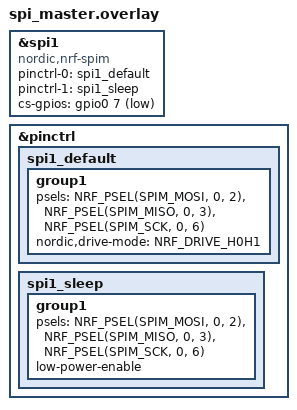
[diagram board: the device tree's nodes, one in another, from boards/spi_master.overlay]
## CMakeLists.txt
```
#
# Copyright (c) 2025 Nordic Semiconductor
#
# SPDX-License-Identifier: LicenseRef-Nordic-5-Clause
#

cmake_minimum_required(VERSION 3.20.0)

find_package(Zephyr REQUIRED HINTS $ENV{ZEPHYR_BASE})
project(nrf91_com_test)

# NORDIC SDK APP START
target_sources(app PRIVATE src/main.c)
target_sources(app PRIVATE src/spi_master_bare.c)
target_sources(app PRIVATE src/spi_slave_bare.c)
target_sources(app PRIVATE src/uart_bare.c)
target_sources(app PRIVATE src/twi_master_bare.c)
target_sources(app PRIVATE src/twi_slave_bare.c)
target_sources(app PRIVATE src/gpio.c)
# NORDIC SDK APP END

zephyr_include_directories(src)
```

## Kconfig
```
#
# Copyright (c) 2020 Nordic Semiconductor ASA
#
# SPDX-License-Identifier: LicenseRef-Nordic-5-Clause
#

menu "Zephyr Kernel"
source "Kconfig.zephyr"
endmenu

# menuconfig MY_SPI_CONFIG
#     bool "Enable SPI Test Mode"

# choice
#     prompt "SPI Mode"
#     default MY_SPI_MASTER

# config MY_SPI_MASTER
#     bool "SPI Master Mode"

# config MY_SPI_SLAVE
#     bool "SPI Slave Mode"

# endchoice
```

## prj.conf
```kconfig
#
# Copyright (c) 2024 Nordic Semiconductor ASA
#
# SPDX-License-Identifier: LicenseRef-Nordic-5-Clause
#
CONFIG_DEBUG_OPTIMIZATIONS=y
CONFIG_DEBUG_THREAD_INFO=y

CONFIG_BOOT_BANNER=n
# CONFIG_UART_CONSOLE=n

CONFIG_POSIX_API=y

CONFIG_GPIO=y
CONFIG_SPI=y
CONFIG_SPI_ASYNC=y
CONFIG_SPI_SLAVE=y
CONFIG_PM_DEVICE=y

CONFIG_I2C=y
CONFIG_I2C_TARGET=y
CONFIG_I2C_NRFX_TWIS_BUF_SIZE=8191

CONFIG_UART_ASYNC_API=y

CONFIG_TFM_LOG_LEVEL_SILENCE=y

CONFIG_DYNAMIC_INTERRUPTS=y
```

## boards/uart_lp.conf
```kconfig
CONFIG_UART_1_ASYNC=y
CONFIG_UART_1_INTERRUPT_DRIVEN=n
CONFIG_UART_1_NRF_HW_ASYNC=y
CONFIG_UART_1_NRF_HW_ASYNC_TIMER=2
CONFIG_UART_1_NRF_ASYNC_LOW_POWER=y
CONFIG_NRFX_TIMER2=y
CONFIG_NRF_SW_LPUART=y
```

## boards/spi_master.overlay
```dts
// To get started, press Ctrl+Space to bring up the completion menu and view the available nodes.

// You can also use the buttons in the sidebar to perform actions on nodes.
// Actions currently available include:

// * Enabling / disabling the node
// * Adding the bus to a bus
// * Removing the node
// * Connecting ADC channels

// For more help, browse the DeviceTree documentation at https://docs.zephyrproject.org/latest/guides/dts/index.html
// You can also visit the nRF DeviceTree extension documentation at https://docs.nordicsemi.com/bundle/nrf-connect-vscode/page/guides/ncs_configure_app.html#devicetree-support-in-the-extension

spi_master:  &spi1 {
	status = "okay";
	compatible = "nordic,nrf-spim";
	pinctrl-0 = <&spi1_default>;
	pinctrl-1 = <&spi1_sleep>;
	pinctrl-names = "default", "sleep";
	cs-gpios = <&gpio0 7 GPIO_ACTIVE_LOW>;
};

&pinctrl {
	spi1_default: spi1_default {
		group1 {
			psels = <NRF_PSEL(SPIM_MOSI, 0, 2)>,
				<NRF_PSEL(SPIM_MISO, 0, 3)>,
				<NRF_PSEL(SPIM_SCK, 0, 6)>;
				nordic,drive-mode = <NRF_DRIVE_H0H1>;
		};
	};
	spi1_sleep: spi1_sleep {
		group1 {
			psels = <NRF_PSEL(SPIM_MOSI, 0, 2)>,
				<NRF_PSEL(SPIM_MISO, 0, 3)>,
				<NRF_PSEL(SPIM_SCK, 0, 6)>;
			low-power-enable;
		};
	};
};
```

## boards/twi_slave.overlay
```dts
// To get started, press Ctrl+Space to bring up the completion menu and view the available nodes.

// You can also use the buttons in the sidebar to perform actions on nodes.
// Actions currently available include:

// * Enabling / disabling the node
// * Adding the bus to a bus
// * Removing the node
// * Connecting ADC channels

// For more help, browse the DeviceTree documentation at https://docs.zephyrproject.org/latest/guides/dts/index.html
// You can also visit the nRF DeviceTree extension documentation at https://docs.nordicsemi.com/bundle/nrf-connect-vscode/page/guides/ncs_configure_app.html#devicetree-support-in-the-extension

twi_slave:  &i2c1 {
	status = "okay";
	compatible = "nordic,nrf-twis";
	pinctrl-0 = <&i2c1_default>;
	pinctrl-1 = <&i2c1_sleep>;
	pinctrl-names = "default", "sleep";
	address-0 = <42>;
};

&pinctrl {
	i2c1_default: i2c1_default {
		group1 {
			psels = <NRF_PSEL(TWIM_SCL, 0, 2)>,
				<NRF_PSEL(TWIM_SDA, 0, 3)>;
			bias-pull-up;
		};
	};

	i2c1_sleep: i2c1_sleep {
		group1 {
			psels = <NRF_PSEL(TWIM_SCL, 0, 2)>,
				<NRF_PSEL(TWIM_SDA, 0, 3)>;
			low-power-enable;
		};
	};
};
```

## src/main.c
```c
/*
 * Copyright (c) 2024 Nordic Semiconductor ASA
 *
 * SPDX-License-Identifier: LicenseRef-Nordic-5-Clause
 *
 */

#include <stdio.h>
#include <unistd.h>
#include <zephyr/kernel.h>
#include <zephyr/logging/log.h>
#include <modem/nrf_modem_lib.h>

#define RED	"\e[0;31m"
#define GREEN	"\e[0;32m"
#define NORMAL	"\e[0m"

uint8_t tx_buffer[8*1024];
uint8_t rx_buffer[8*1024];

/* Keeping UARTE0 on drains a bit of power */
int lp_printf(const char *fmt, ...)
{
	va_list args;
	int ret;

	NRF_UARTE0_NS->ENABLE = UARTE_ENABLE_ENABLE_Enabled;

	va_start(args, fmt);
	ret = vprintf(fmt, args);
	va_end(args);

	while (!NRF_UARTE0_NS->EVENTS_ENDTX) {
		usleep(1000);
	}
	NRF_UARTE0_NS->ENABLE = 0;

	return ret;
}

void lp_print_rx(int received, int expected)
{
	lp_printf("Received %d bytes %02x%02x%02x%02x %02x%02x%02x%02x ... ", received,
			rx_buffer[0], rx_buffer[1], rx_buffer[2], rx_buffer[3],
			rx_buffer[4], rx_buffer[5], rx_buffer[6], rx_buffer[7]);

	if (received != expected) {
		lp_printf(RED "Instead of %d bytes" NORMAL, expected);
		return;

	}

	if (received != (rx_buffer[0] << 8) + rx_buffer[1]) {
		lp_printf(RED "Packet header indicates %d bytes" NORMAL,
			  (rx_buffer[0] << 8) + rx_buffer[1]);
		return;
	}

	for (int i = 2; i < received; i++) {
		if (rx_buffer[i] != (i & 0xff)) {
			lp_printf(RED "Mismatch in byte %d" NORMAL" expected %02x got %02x\n", i,
				  i & 0xff, rx_buffer[i]);
			return;
		}
	}

	lp_printf(GREEN "OK\n" NORMAL);
}

uint8_t lp_get(void)
{
	static uint8_t input;

	NRF_UARTE0_NS->ENABLE = UARTE_ENABLE_ENABLE_Enabled;

	NRF_UARTE0_NS->RXD.PTR = (int)&input;
	NRF_UARTE0_NS->RXD.MAXCNT = 1;
	NRF_UARTE0_NS->EVENTS_ENDRX = 0;
	NRF_UARTE0_NS->TASKS_STARTRX = 1;

	while (!NRF_UARTE0_NS->EVENTS_ENDRX) {
		usleep(100000);
	}

	NRF_UARTE0_NS->TASKS_STOPRX = 1;

	NRF_UARTE0_NS->ENABLE = 0;

	return input;
}

#if DT_NODE_EXISTS(DT_NODELABEL(spi_master))

/* west build -b nrf9151dk/nrf9151/ns --pristine -- -DDTC_OVERLAY_FILE=boards/spi_master.overlay */
#include "spi_master_dt.c"

#elif DT_NODE_EXISTS(DT_NODELABEL(spi_slave))

/* west build -b nrf9151dk/nrf9151/ns --pristine -- -DDTC_OVERLAY_FILE=boards/spi_slave.overlay */
#include "spi_slave_dt.c"

#elif DT_NODE_EXISTS(DT_NODELABEL(uart))

/* west build -b nrf9151dk/nrf9151/ns --pristine -- -DDTC_OVERLAY_FILE=boards/uart.overlay */
#include "uart_dt.c"

#elif DT_NODE_EXISTS(DT_NODELABEL(uart_lp))

/* west build -b nrf9151dk/nrf9151/ns --pristine -- -DDTC_OVERLAY_FILE=boards/uart_lp.overlay \
 * -DEXTRA_CONF_FILE=boards/uart_lp.conf
 */
#include "uart_lp_dt.c"

#elif DT_NODE_EXISTS(DT_NODELABEL(twi_master))

/* west build -b nrf9151dk/nrf9151/ns --pristine -- -DDTC_OVERLAY_FILE=boards/twi_master.overlay */
#include "twi_master_dt.c"

#elif DT_NODE_EXISTS(DT_NODELABEL(twi_slave))
/* Doesn't work, not supported? */
/* west build -b nrf9151dk/nrf9151/ns --pristine -- -DDTC_OVERLAY_FILE=boards/twi_slave.overlay */
#include "twi_slave_dt.c"
#else

/* Not using device tree, use runtime test selection using UART0. */

#define RAW_TEST

void spim_init(uint32_t bitrate);
int spim_send(int size);
int spim_send_delayed(int size);
int spim_recv(int size);
int spim_recv_delayed(int size);
void spim_deinit(void);

void spis_init(uint32_t bitrate);
int spis_send(int size);
int spis_recv(int size);
void spis_deinit(void);

void uart_init(uint32_t bitrate);
int uart_send(int size);
int uart_recv(int size);
void uart_deinit(void);

void uart_timeout_init(uint32_t bitrate);
void uart_timeout_deinit(void);

void uart_lp_init(uint32_t bitrate);
int uart_lp_send(int size);
int uart_lp_recv(int size);

void twim_init(uint32_t bitrate);
int twim_send(int size);
int twim_recv(int size);
void twim_deinit(void);

void twis_init(uint32_t bitrate);
int twis_send(int size);
int twis_recv(int size);
void twis_deinit(void);

void gpio_init(uint32_t bitrate);
int gpio_send(int size);
int gpio_recv(int size);
void gpio_deinit(void);

int no_send(int size)
{
	return 0;
}

int no_recv(int size)
{
	return 0;
}

void no_deinit(void)
{

}

int (*send)(int size) = no_send;
int (*recv)(int size) = no_recv;
void (*deinit)(void) = no_deinit;

typedef struct {
	char *label;
	void (*init)(uint32_t);
	uint32_t bitrate;
	int (*send)(int);
	int (*recv)(int);
	void (*deinit)(void);
} device_option_t;

char *select_device(void)
{
	char input;
	int index;
	device_option_t device_menu[] = {
		{"None (measure idle power)", NULL, 0, no_send, no_recv, no_deinit},
		{"SPI master @ 125 kbps with increased CSN to CLK delay", spim_init,
				SPIM_FREQUENCY_FREQUENCY_K125,
				spim_send_delayed, spim_recv_delayed, spim_deinit},
		{"SPI master @ 1 Mbps with increased CSN to CLK delay", spim_init,
				SPIM_FREQUENCY_FREQUENCY_M1,
				spim_send_delayed, spim_recv_delayed, spim_deinit},
		{"SPI master @ 1 Mbps", spim_init, SPIM_FREQUENCY_FREQUENCY_M1,
				spim_send, spim_recv, spim_deinit},
		{"SPI master @ 8 Mbps with increased CSN to CLK delay", spim_init,
				SPIM_FREQUENCY_FREQUENCY_M8,
				spim_send_delayed, spim_recv_delayed, spim_deinit},
		{"SPI slave", spis_init, 0, spis_send, spis_recv, spis_deinit},
		{"UART @ 115.2 kbps", uart_init, UARTE_BAUDRATE_BAUDRATE_Baud115200,
				uart_send, uart_recv, uart_deinit},
		{"UART @ 1 Mbps", uart_init, UARTE_BAUDRATE_BAUDRATE_Baud1M,
				uart_send, uart_recv, uart_deinit},
		{"UART @ 2 Mbps", uart_init, 2 * UARTE_BAUDRATE_BAUDRATE_Baud1M,
				uart_send, uart_recv, uart_deinit},
		{"UART with RX timeout @ 1 Mbps", uart_timeout_init, UARTE_BAUDRATE_BAUDRATE_Baud1M,
				uart_send, uart_recv, uart_timeout_deinit},
		{"UART with enable pins @ 1 Mbps", uart_lp_init, UARTE_BAUDRATE_BAUDRATE_Baud1M,
				uart_lp_send, uart_lp_recv, uart_deinit},
		{"TWI master @ 100 kbps", twim_init, TWIM_FREQUENCY_FREQUENCY_K100,
				twim_send, twim_recv, twim_deinit},
		{"TWI master @ 250 kbps", twim_init, TWIM_FREQUENCY_FREQUENCY_K250,
				twim_send, twim_recv, twim_deinit},
		{"TWI master @ 400 kbps", twim_init, TWIM_FREQUENCY_FREQUENCY_K400,
				twim_send, twim_recv, twim_deinit},
		{"TWI slave", twis_init, 0, twis_send, twis_recv, twis_deinit},
		{"GPIO interrupt response timing", gpio_init, 0, gpio_send, gpio_recv, gpio_deinit},
	};

	lp_printf("\nSelect peripheral:\n");
	for (index = 0; index < ARRAY_SIZE(device_menu); index++) {
		lp_printf("  %c. %s\n", 'a' + index, device_menu[index].label);
	}

	lp_printf("Configuration:\n");
	lp_printf("  [. Constant latency (keep clock on)\n");
	lp_printf("  ]. Low power mode (disable clock while idle)\n");

	input = lp_get();

	if (input == '[') {
		lp_printf("Switching to Constant latency mode\n", input);
		NRF_POWER_NS->TASKS_CONSTLAT = 1;
		return "";
	}
	if (input == ']') {
		lp_printf("Switching to low power mode\n", input);
		NRF_POWER_NS->TASKS_LOWPWR = 1;
		return "";
	}
	if (input < 'a' || input >= 'a' + ARRAY_SIZE(device_menu)) {
		lp_printf("Invalid selection '%c'\n", input);
		return "";
	}

	index = input - 'a';

	lp_printf("Selected device '%s'\n", device_menu[index].label);

	if (device_menu[index].init) {
		device_menu[index].init(device_menu[index].bitrate);
	}
	send = device_menu[index].send;
	recv = device_menu[index].recv;
	deinit = device_menu[index].deinit;

	return device_menu[index].label;
}

#endif


typedef struct {
	const char *label;
	int size;
	int (*func)(int);
} test_option_t;

int sleep_10(int size)
{
	return sleep(10);
}

int set_size_and_send(int size)
{
	tx_buffer[0] = size >> 8;
	tx_buffer[1] = size & 0xff;
	return send(size);
}

bool run_test(void)
{
	int ret;
	int input;
	test_option_t test_menu[] = {
		{"Sleep 10 s", 0, sleep_10},
		{"Send 16 bytes", 16, set_size_and_send},
		{"Send 1024 bytes", 1024, set_size_and_send},
		{"Send 8 kbytes", 8 * 1024 - 2, set_size_and_send},
		{"Receive 16 bytes", 16, recv},
		{"Receive 1024 bytes", 1024, recv},
		{"Receive 8 kbytes", 8 * 1024 - 2, recv},
	};

	lp_printf("\nSelect test:\n");
	for (int i = 0; i < ARRAY_SIZE(test_menu); i++) {
		lp_printf("  %c. %s\n", '1' + i, test_menu[i].label);
	}
	lp_printf("  Esc. Disable device\n");

	input = lp_get();

	if (input == '\e') {
		lp_printf("Disable device\n");
		return false;
	}

	input -= '1';

	if (input < 0 || input >= ARRAY_SIZE(test_menu)) {
		/* Invalid selection. */
		lp_printf("Invalid selection '%c'\n", input + '1');
		return true;
	}

	lp_printf("Selected test '%s'\n", test_menu[input].label);

	sleep(1);

	ret = test_menu[input].func(test_menu[input].size);

	sleep(1);

	if (ret == 0) {
		lp_printf("Test done\n", ret);
	} else if (ret < 0) {
		lp_printf(RED "Test returned %d\n" NORMAL, ret);
	} else {
		if (test_menu[input].label[0] == 'R') {
			lp_print_rx(ret, test_menu[input].size);
		} else if (test_menu[input].size != ret) {
			lp_printf("Send %d bytes " RED "instead of %d bytes" NORMAL "\n", ret,
				  test_menu[input].size);
		} else {
			lp_printf("Send %d bytes " GREEN "OK" NORMAL "\n", ret);
		}
	}

	return true;
}


int main(void)
{
	/* Modem is not used but always needs to be initialised to prevent 3 mA power drain. */
	nrf_modem_lib_init();

	/* Disable UART0 to reduce power. */
	NRF_UARTE0_NS->TASKS_STOPRX = 1;
	NRF_UARTE0_NS->INTEN = 0;
	NRF_UARTE0_NS->ENABLE = 0;

	lp_printf("Sample has started\n");

	for (int i = 0; i < sizeof(tx_buffer); i++) {
		tx_buffer[i] = i;
	}

	while (1) {
#ifdef RAW_TEST
		char *test_name = select_device();

		if (strlen(test_name) == 0) {
			continue;
		}
#else
		init();
#endif

		while (run_test());

		deinit();
		sleep(1);

#ifdef RAW_TEST
		lp_printf("'%s' disabled\n", test_name);
#endif
	}
}
```

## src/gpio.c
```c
/*
 * Copyright (c) 2024 Nordic Semiconductor ASA
 *
 * SPDX-License-Identifier: LicenseRef-Nordic-5-Clause
 *
 */

#include <stdio.h>
#include <unistd.h>
#include <zephyr/kernel.h>

#define GPIO        NRF_P0_NS
#define GPIOTE      NRF_GPIOTE1_NS

#define PIN_INPUT   8		/* BUTTON1 */
#define PIN_OUTPUT  0		/* LED1 */

int lp_printf(const char *fmt, ...);

static bool test_done;

 void gpio_init(uint32_t bitrate)
{
	/* Enable output pin to low. */
	GPIO->OUTCLR = 1 << PIN_OUTPUT;
	GPIO->PIN_CNF[PIN_OUTPUT] = GPIO_PIN_CNF_DIR_Output << GPIO_PIN_CNF_DIR_Pos;

	/* Enable input pin with pullup. */
	GPIO->PIN_CNF[PIN_INPUT] = GPIO_PIN_CNF_PULL_Pullup << GPIO_PIN_CNF_PULL_Pos;

	lp_printf("    Input   P0.%02d\n", PIN_INPUT);
	lp_printf("    Output  P0.%02d\n", PIN_OUTPUT);
	lp_printf("Select 'Receive' and pull input low to measure response time on output\n");
}

int gpio_send(int size)
{
	/* Output pin high. */
	GPIO->OUTSET = 1 << PIN_OUTPUT;

	sleep(1);

	/* Output pin low. */
	GPIO->OUTCLR = 1 << PIN_OUTPUT;

	return 0;
}

void gpiote_isr(const void *arg)
{
	/* Output pin low. */
	GPIO->OUTCLR = 1 << PIN_OUTPUT;

	/* Clear interrupt. */
	GPIOTE->INTENCLR = GPIOTE_INTENCLR_IN0_Msk;

	test_done = true;
}

int gpio_recv(int size)
{
	test_done = false;

	/* Output pin high. */
	GPIO->OUTSET = 1 << PIN_OUTPUT;

	/* Enable interrupt. */
	GPIOTE->CONFIG[0] = GPIOTE_CONFIG_MODE_Event << GPIOTE_CONFIG_MODE_Pos |
			    PIN_INPUT << GPIOTE_CONFIG_PSEL_Pos |
			    GPIOTE_CONFIG_POLARITY_HiToLo << GPIOTE_CONFIG_POLARITY_Pos;
	GPIOTE->EVENTS_IN[0] = 0;
	GPIOTE->INTENSET = GPIOTE_INTENSET_IN0_Msk;
	irq_connect_dynamic(GPIOTE1_IRQn, 0, gpiote_isr, NULL, 0);
	irq_enable(GPIOTE1_IRQn);

	while (!test_done) {
		__WFI();
	}

	/* Disable interrupt. */
	irq_disable(GPIOTE1_IRQn);
	GPIOTE->INTENCLR = GPIOTE_INTENCLR_IN0_Msk;

	/* Output pin low. */
	GPIO->OUTCLR = 1 << PIN_OUTPUT;

	return 0;//87.8 µs 11.5 µs 76.3
}

void gpio_deinit(void)
{
	/* Disable output pin. */
	GPIO->OUTCLR = 1 << PIN_OUTPUT;
	GPIO->PIN_CNF[PIN_OUTPUT] = 0;

	/* Disable input pin. */
	GPIO->PIN_CNF[PIN_INPUT] = 0;
}
```

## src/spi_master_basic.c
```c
/*
 * Copyright (c) 2024 Nordic Semiconductor ASA
 *
 * SPDX-License-Identifier: LicenseRef-Nordic-5-Clause
 *
 */

#include <stdio.h>
#include <unistd.h>
#include <zephyr/kernel.h>

#define SPI_MASTER NRF_SPIM1_NS
#define GPIO       NRF_P0_NS
#define PIN_SCK    6
#define PIN_MISO   3
#define PIN_MOSI   2
#define PIN_CS     7

extern uint8_t tx_buffer[1024];
extern uint8_t rx_buffer[2048];

int lp_printf(const char *fmt, ...);

K_SEM_DEFINE(spim_done, 0, 1);

void spim_isr(const void *arg)
{
	SPI_MASTER->EVENTS_END = 0;
	k_sem_give(&spim_done);
}

void spim_init(uint32_t bitrate)
{
	/* MISO: Dir input, input connect, pull disabled, drive s0s1, sense disabled. */
	GPIO->PIN_CNF[PIN_MISO] = 0;

	/* Configure pins. */
	SPI_MASTER->PSEL.SCK = PIN_SCK;
	SPI_MASTER->PSEL.MOSI = PIN_MOSI;
	SPI_MASTER->PSEL.MISO = PIN_MISO;

	/* Configure buffers. */
	SPI_MASTER->RXD.PTR = (int)rx_buffer;
	SPI_MASTER->TXD.PTR = (int)tx_buffer;

	/* Most significant bit first, Sample on trailing edge, Active low.  */
	SPI_MASTER->CONFIG = SPIS_CONFIG_CPOL_Msk | SPIS_CONFIG_CPHA_Msk;

	/* Frequency */
	SPI_MASTER->FREQUENCY = bitrate;

	/* Enable interrupt to wake up at the end of a message. */
	SPI_MASTER->INTENSET = SPIM_INTENSET_END_Msk;
	irq_connect_dynamic(SPIM1_SPIS1_TWIM1_TWIS1_UARTE1_IRQn, 0, spim_isr, NULL, 0);
	irq_enable(SPIM1_SPIS1_TWIM1_TWIS1_UARTE1_IRQn);

	/* Enable. */
	SPI_MASTER->ENABLE = SPIM_ENABLE_ENABLE_Enabled;

	/* SCK: Dir output, input disconnect, pull disabled, drive h0h1, sense disabled. */
	GPIO->PIN_CNF[PIN_SCK] = (GPIO_PIN_CNF_DIR_Output << GPIO_PIN_CNF_DIR_Pos) |
				 (GPIO_PIN_CNF_INPUT_Disconnect << GPIO_PIN_CNF_INPUT_Pos) |
				 (GPIO_PIN_CNF_DRIVE_H0H1 << GPIO_PIN_CNF_DRIVE_Pos);
	/* MOSI: Dir output, input disconnect, pull disabled, drive h0h1, sense disabled. */
	GPIO->PIN_CNF[PIN_MOSI] = (GPIO_PIN_CNF_DIR_Output << GPIO_PIN_CNF_DIR_Pos) |
				  (GPIO_PIN_CNF_INPUT_Disconnect << GPIO_PIN_CNF_INPUT_Pos) |
				  (GPIO_PIN_CNF_DRIVE_H0H1 << GPIO_PIN_CNF_DRIVE_Pos);
	/* CS: high. */
	GPIO->OUTSET = 1 << PIN_CS;
	/* CS: Dir output, input disconnect, pull disabled, drive h0h1, sense disabled. */
	GPIO->PIN_CNF[PIN_CS] = (GPIO_PIN_CNF_DIR_Output << GPIO_PIN_CNF_DIR_Pos) |
				(GPIO_PIN_CNF_INPUT_Disconnect << GPIO_PIN_CNF_INPUT_Pos) |
				(GPIO_PIN_CNF_DRIVE_H0H1 << GPIO_PIN_CNF_DRIVE_Pos);

	lp_printf("    SCK     P0.%02d\n", PIN_SCK);
	lp_printf("    MOSI    P0.%02d\n", PIN_MOSI);
	lp_printf("    MISO    P0.%02d\n", PIN_MISO);
	lp_printf("    CS      P0.%02d\n", PIN_CS);
}

int spim_send(int size)
{
	SPI_MASTER->TXD.MAXCNT = size;
	SPI_MASTER->RXD.MAXCNT = 0;

	/* CS: low. */
	GPIO->OUTCLR = 1 << PIN_CS;

	SPI_MASTER->TASKS_START = 1;

	k_sem_take(&spim_done, K_FOREVER);

	/* CS: high. */
	GPIO->OUTSET = 1 << PIN_CS;

	return SPI_MASTER->TXD.AMOUNT;
}

int spim_send_delayed(int size)
{
	SPI_MASTER->TXD.MAXCNT = size;
	SPI_MASTER->RXD.MAXCNT = 0;

	/* CS: low. */
	GPIO->OUTCLR = 1 << PIN_CS;

	usleep(80);

	SPI_MASTER->TASKS_START = 1;

	k_sem_take(&spim_done, K_FOREVER);

	usleep(1);

	/* CS: high. */
	GPIO->OUTSET = 1 << PIN_CS;

	return SPI_MASTER->TXD.AMOUNT;
}

int spim_recv(int size)
{
	SPI_MASTER->TXD.MAXCNT = 0;
	SPI_MASTER->RXD.MAXCNT = size;

	/* CS: low. */
	GPIO->OUTCLR = 1 << PIN_CS;

	SPI_MASTER->TASKS_START = 1;

	k_sem_take(&spim_done, K_FOREVER);

	/* CS: high. */
	GPIO->OUTSET = 1 << PIN_CS;

	return SPI_MASTER->RXD.AMOUNT;
}

int spim_recv_delayed(int size)
{
	SPI_MASTER->TXD.MAXCNT = 0;
	SPI_MASTER->RXD.MAXCNT = size;

	/* CS: low. */
	GPIO->OUTCLR = 1 << PIN_CS;

	usleep(80);

	SPI_MASTER->TASKS_START = 1;

	k_sem_take(&spim_done, K_FOREVER);

	usleep(1);

	/* CS: high. */
	GPIO->OUTSET = 1 << PIN_CS;

	return SPI_MASTER->RXD.AMOUNT;
}

void spim_deinit(void)
{
	SPI_MASTER->INTENCLR = SPIM_INTENCLR_END_Msk;
	GPIO->PIN_CNF[PIN_SCK] = 0;
	GPIO->PIN_CNF[2] = 0;
	GPIO->PIN_CNF[PIN_CS] = 0;
	SPI_MASTER->ENABLE = 0;
}
```

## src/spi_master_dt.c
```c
/*
 * Copyright (c) 2024 Nordic Semiconductor ASA
 *
 * SPDX-License-Identifier: LicenseRef-Nordic-5-Clause
 *
 */

#include <zephyr/drivers/spi.h>
#include <zephyr/pm/device.h>

#define USED_DEV DT_NODELABEL(spi_master)
#define DT_DRV_COMPAT nordic_nrf_spim
#define SPI_MASTER NRF_SPIM1_NS

const struct device *p_dev;
struct spi_config spi_cfg = {
	.operation = SPI_WORD_SET(8) | SPI_TRANSFER_MSB | SPI_MODE_CPOL | SPI_MODE_CPHA,
	.frequency = 1000000,
	.slave = 0,
	.cs.gpio = GPIO_DT_SPEC_INST_GET(0, cs_gpios),
	.cs.delay = 100,
};

void init(void)
{
	p_dev = DEVICE_DT_GET(USED_DEV);

	if (p_dev == NULL) {
		lp_printf("Could not get device\n");
		return;
	}
	lp_printf("\nUsing SPI Master device: %s\n", p_dev->name);
	lp_printf("    SCK     P0.%02d\n", SPI_MASTER->PSEL.SCK);
	lp_printf("    MOSI    P0.%02d\n", SPI_MASTER->PSEL.MOSI);
	lp_printf("    MISO    P0.%02d\n", SPI_MASTER->PSEL.MISO);
	lp_printf("    CS      P0.%02d\n", spi_cfg.cs.gpio.pin);

	pm_device_action_run(p_dev, PM_DEVICE_ACTION_RESUME);
}

int send(int size)
{
	int err;

	const struct spi_buf tx_buf = {
		.buf = tx_buffer,
		.len = size
	};
	const struct spi_buf_set tx = {
		.buffers = &tx_buf,
		.count = 1
	};

	err = spi_write(p_dev, &spi_cfg, &tx);

	return err == 0 ? size : err;
}

int recv(int size)
{
	int err;

	struct spi_buf rx_buf = {
		.buf = rx_buffer,
		.len = size,
	};
	const struct spi_buf_set rx = {
		.buffers = &rx_buf,
		.count = 1
	};

	err = spi_read(p_dev, &spi_cfg, &rx);

	return err == 0 ? size : err;
}

void deinit(void)
{
	spi_release(p_dev, &spi_cfg);
	/* Suspend is needed to re-initialise SPIM so we can change the frequency. */
	pm_device_action_run(p_dev, PM_DEVICE_ACTION_SUSPEND);
}
```

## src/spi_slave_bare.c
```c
/*
 * Copyright (c) 2024 Nordic Semiconductor ASA
 *
 * SPDX-License-Identifier: LicenseRef-Nordic-5-Clause
 *
 */

#include <stdio.h>
#include <unistd.h>
#include <zephyr/kernel.h>

#define SPI_SLAVE NRF_SPIS1_NS
#define GPIO      NRF_P0_NS
#define PIN_SCK    6
#define PIN_MISO   3
#define PIN_MOSI   2
#define PIN_CS     7

extern uint8_t tx_buffer[1024];
extern uint8_t rx_buffer[2048];

K_SEM_DEFINE(spis_done, 0, 1);

int lp_printf(const char *fmt, ...);

static void spis_isr(const void *arg)
{
	SPI_SLAVE->EVENTS_END = 0;
	k_sem_give(&spis_done);
}

void spis_init(uint32_t bitrate)
{
	/* SCK: Dir input, input connect, pull disabled, drive s0s1, sense disabled. */
	GPIO->PIN_CNF[PIN_SCK] = 0;
	/* MOSI: Dir input, input connect, pull disabled, drive s0s1, sense disabled. */
	GPIO->PIN_CNF[PIN_MOSI] = 0;
	/* CSN: Dir input, input connect, pull disabled, drive s0s1, sense disabled. */
	GPIO->PIN_CNF[PIN_CS] = 0;

	/* Configure pins. */
	SPI_SLAVE->PSEL.SCK = PIN_SCK;
	SPI_SLAVE->PSEL.MISO = PIN_MISO;
	SPI_SLAVE->PSEL.MOSI = PIN_MOSI;
	SPI_SLAVE->PSEL.CSN = PIN_CS;

	/* Configure buffers. */
	SPI_SLAVE->RXD.PTR = (int)rx_buffer;
	SPI_SLAVE->TXD.PTR = (int)tx_buffer;

	/* Most significant bit first, Sample on trailing edge, Active low.  */
	SPI_SLAVE->CONFIG = SPIS_CONFIG_CPOL_Msk | SPIS_CONFIG_CPHA_Msk;

	/* Equire semaphore on end of transmission. */
	SPI_SLAVE->SHORTS = SPIS_SHORTS_END_ACQUIRE_Msk;

	/* Enable interrupt to wake up at the end of a message. */
	SPI_SLAVE->INTENSET = SPIS_INTENSET_END_Msk;
	irq_connect_dynamic(SPIM1_SPIS1_TWIM1_TWIS1_UARTE1_IRQn, 0, spis_isr, NULL, 0);
	irq_enable(SPIM1_SPIS1_TWIM1_TWIS1_UARTE1_IRQn);

	/* Enable. */
	SPI_SLAVE->ENABLE = SPIS_ENABLE_ENABLE_Enabled;

	/* MISO: Dir output, input disconnect, pull disabled, drive h0h1, sense disabled. */
	GPIO->PIN_CNF[PIN_MISO] = (GPIO_PIN_CNF_DIR_Output << GPIO_PIN_CNF_DIR_Pos) |
				  (GPIO_PIN_CNF_INPUT_Disconnect << GPIO_PIN_CNF_INPUT_Pos) |
				  (GPIO_PIN_CNF_DRIVE_H0H1 << GPIO_PIN_CNF_DRIVE_Pos);

	lp_printf("    SCK     P0.%02d\n", PIN_SCK);
	lp_printf("    MOSI    P0.%02d\n", PIN_MOSI);
	lp_printf("    MISO    P0.%02d\n", PIN_MISO);
	lp_printf("    CS      P0.%02d\n", PIN_CS);
}

int spis_send(int size)
{
	SPI_SLAVE->TXD.MAXCNT = size;
	SPI_SLAVE->RXD.MAXCNT = 0;
	SPI_SLAVE->TASKS_RELEASE = 1;

	if (k_sem_take(&spis_done,  K_SECONDS(60))) {
		SPI_SLAVE->TASKS_ACQUIRE = 1;
		return -ETIMEDOUT;
	}

	return SPI_SLAVE->TXD.AMOUNT;
}

int spis_recv(int size)
{
	SPI_SLAVE->TXD.MAXCNT = 0;
	SPI_SLAVE->RXD.MAXCNT = size;
	SPI_SLAVE->TASKS_RELEASE = 1;

	if (k_sem_take(&spis_done,  K_SECONDS(60))) {
		SPI_SLAVE->TASKS_ACQUIRE = 1;
		return -ETIMEDOUT;
	}

	return SPI_SLAVE->RXD.AMOUNT;
}

void spis_deinit(void)
{
	SPI_SLAVE->INTENCLR = SPIS_INTENCLR_END_Msk;
	GPIO->PIN_CNF[PIN_MISO] = 0;
	SPI_SLAVE->ENABLE = 0;
}
```

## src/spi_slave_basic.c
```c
/*
 * Copyright (c) 2024 Nordic Semiconductor ASA
 *
 * SPDX-License-Identifier: LicenseRef-Nordic-5-Clause
 *
 */

#include <stdio.h>
#include <unistd.h>
#include <zephyr/kernel.h>

#define SPI_SLAVE NRF_SPIS1_NS
#define GPIO      NRF_P0_NS
#define PIN_SCK    6
#define PIN_MISO   3
#define PIN_MOSI   2
#define PIN_CS     7

extern uint8_t tx_buffer[1024];
extern uint8_t rx_buffer[2048];

int lp_printf(const char *fmt, ...);

static bool transfer_done = false;

static void spis_isr(const void *arg)
{
	transfer_done = true;
	SPI_SLAVE->EVENTS_END = 0;
}

void spis_init(uint32_t bitrate)
{
	/* SCK: Dir input, input connect, pull disabled, drive s0s1, sense disabled. */
	GPIO->PIN_CNF[PIN_SCK] = 0;
	/* MOSI: Dir input, input connect, pull disabled, drive s0s1, sense disabled. */
	GPIO->PIN_CNF[PIN_MOSI] = 0;
	/* CSN: Dir input, input connect, pull disabled, drive s0s1, sense disabled. */
	GPIO->PIN_CNF[PIN_CS] = 0;

	/* Configure pins. */
	SPI_SLAVE->PSEL.SCK = PIN_SCK;
	SPI_SLAVE->PSEL.MISO = PIN_MISO;
	SPI_SLAVE->PSEL.MOSI = PIN_MOSI;
	SPI_SLAVE->PSEL.CSN = PIN_CS;

	/* Configure buffers. */
	SPI_SLAVE->RXD.PTR = (int)rx_buffer;
	SPI_SLAVE->TXD.PTR = (int)tx_buffer;

	/* Most significant bit first, Sample on trailing edge, Active low.  */
	SPI_SLAVE->CONFIG = SPIS_CONFIG_CPOL_Msk | SPIS_CONFIG_CPHA_Msk;

	/* Equire semaphore on end of transmission. */
	SPI_SLAVE->SHORTS = SPIS_SHORTS_END_ACQUIRE_Msk;

	/* Enable interrupt to wake up at the end of a message. */
	SPI_SLAVE->INTENSET = SPIS_INTENSET_END_Msk;
	irq_connect_dynamic(SPIM1_SPIS1_TWIM1_TWIS1_UARTE1_IRQn, 0, spis_isr, NULL, 0);
	irq_enable(SPIM1_SPIS1_TWIM1_TWIS1_UARTE1_IRQn);

	/* Enable. */
	SPI_SLAVE->ENABLE = SPIS_ENABLE_ENABLE_Enabled;

	/* MISO: Dir output, input disconnect, pull disabled, drive h0h1, sense disabled. */
	GPIO->PIN_CNF[PIN_MISO] = (GPIO_PIN_CNF_DIR_Output << GPIO_PIN_CNF_DIR_Pos) |
				  (GPIO_PIN_CNF_INPUT_Disconnect << GPIO_PIN_CNF_INPUT_Pos) |
				  (GPIO_PIN_CNF_DRIVE_H0H1 << GPIO_PIN_CNF_DRIVE_Pos);

	lp_printf("    SCK     P0.%02d\n", PIN_SCK);
	lp_printf("    MOSI    P0.%02d\n", PIN_MOSI);
	lp_printf("    MISO    P0.%02d\n", PIN_MISO);
	lp_printf("    CS      P0.%02d\n", PIN_CS);
}

int spis_send(int size)
{
	SPI_SLAVE->TXD.MAXCNT = size;
	SPI_SLAVE->RXD.MAXCNT = 0;
	SPI_SLAVE->TASKS_RELEASE = 1;

	while (!transfer_done) {
		__WFI();
	}

	transfer_done = false;

	return SPI_SLAVE->TXD.AMOUNT;
}

int spis_recv(int size)
{
	SPI_SLAVE->TXD.MAXCNT = 0;
	SPI_SLAVE->RXD.MAXCNT = size;
	SPI_SLAVE->TASKS_RELEASE = 1;

	while (!transfer_done) {
		__WFI();
	}

	transfer_done = false;

	return SPI_SLAVE->RXD.AMOUNT;
}

void spis_deinit(void)
{
	SPI_SLAVE->INTENCLR = SPIS_INTENCLR_END_Msk;
	GPIO->PIN_CNF[PIN_MISO] = 0;
	SPI_SLAVE->ENABLE = 0;
}
```

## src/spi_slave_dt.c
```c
/*
 * Copyright (c) 2024 Nordic Semiconductor ASA
 *
 * SPDX-License-Identifier: LicenseRef-Nordic-5-Clause
 *
 */

#include <zephyr/drivers/spi.h>
#include <../../modules/hal/nordic/nrfx/hal/nrf_spis.h>

#define USED_DEV DT_NODELABEL(spi_slave)
#define SPI_SLAVE NRF_SPIS1_NS

const struct device *p_dev;

void init(void)
{
	p_dev = DEVICE_DT_GET(USED_DEV);

	if (p_dev == NULL) {
		lp_printf("Could not get device\n");
		return;
	}
	lp_printf("\nUsing SPI Slave device: %s\n", p_dev->name);
	lp_printf("    SCK     P0.%02d\n", SPI_SLAVE->PSEL.SCK);
	lp_printf("    MOSI    P0.%02d\n", SPI_SLAVE->PSEL.MOSI);
	lp_printf("    MISO    P0.%02d\n", SPI_SLAVE->PSEL.MISO);
	lp_printf("    CS      P0.%02d\n", SPI_SLAVE->PSEL.CSN);
}

static const struct spi_config spi_cfg = {
	.operation = SPI_WORD_SET(8) | SPI_TRANSFER_MSB | SPI_OP_MODE_SLAVE |
		     SPI_MODE_CPOL | SPI_MODE_CPHA,
	.frequency = 1000000,
	.slave = 1,
};

int send(int size)
{
	const struct spi_buf tx_buf = {
		.buf = tx_buffer,
		.len = size
	};
	const struct spi_buf_set tx = {
		.buffers = &tx_buf,
		.count = 1
	};

	/* Always returns 0, how do we tell how many bytes were send? */
	return spi_write(p_dev, &spi_cfg, &tx);
}

int recv(int size)
{
	struct spi_buf rx_buf = {
		.buf = rx_buffer,
		.len = size
	};
	const struct spi_buf_set rx = {
		.buffers = &rx_buf,
		.count = 1
	};

	return spi_read(p_dev, &spi_cfg, &rx);
}

void deinit(void)
{

}
```

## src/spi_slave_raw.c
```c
/*
 * Copyright (c) 2024 Nordic Semiconductor ASA
 *
 * SPDX-License-Identifier: LicenseRef-Nordic-5-Clause
 *
 */

#include <stdio.h>
#include <unistd.h>
#include <zephyr/kernel.h>
#include <zephyr/logging/log.h>
LOG_MODULE_REGISTER(spi, LOG_LEVEL_DBG);

#define SPI_SLAVE NRF_SPIS1_NS
#define GPIO      NRF_P0_NS

extern uint8_t tx_buffer[1024];
extern uint8_t rx_buffer[2048];

void spi_slave_init(void)
{
	GPIO->PIN_CNF[2] = 0x300;
	GPIO->PIN_CNF[3] = 0x302;
	GPIO->PIN_CNF[6] = 0x300;
	GPIO->PIN_CNF[7] = 0x300;

	SPI_SLAVE->PSEL.SCK = 6;
	SPI_SLAVE->PSEL.MISO = 3;
	SPI_SLAVE->PSEL.MOSI = 2;
	SPI_SLAVE->PSEL.CSN = 7;
	SPI_SLAVE->RXD.PTR = (int)rx_buffer;
	SPI_SLAVE->RXD.MAXCNT = sizeof(rx_buffer);
	SPI_SLAVE->TXD.PTR = (int)tx_buffer;
	SPI_SLAVE->TXD.MAXCNT = sizeof(tx_buffer);
	SPI_SLAVE->CONFIG = SPIS_CONFIG_CPOL_Msk | SPIS_CONFIG_CPHA_Msk;
	SPI_SLAVE->SHORTS = 4;
	SPI_SLAVE->ENABLE = 2;

	SPI_SLAVE->TASKS_RELEASE = 1;
}

void spi_slave_test(size_t size)
{
	while (1) {
		while (!SPI_SLAVE->EVENTS_END) {
			sleep(1);
		}

		printf("\nReceived %d\n", SPI_SLAVE->RXD.AMOUNT);
		printf("success %d: %02x %02x %02x %02x\n", (rx_buffer[0] << 8) + rx_buffer[1],
		       rx_buffer[2], rx_buffer[3], rx_buffer[4], rx_buffer[5]);
		printf("status %x\n", SPI_SLAVE->STATUS);
		printf("send %d\n", SPI_SLAVE->TXD.AMOUNT);
		SPI_SLAVE->EVENTS_END = 0;
		SPI_SLAVE->TASKS_RELEASE = 1;
	}
}

void spi_slave_deinit(void)
{

}
```

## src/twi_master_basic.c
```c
/*
 * Copyright (c) 2024 Nordic Semiconductor ASA
 *
 * SPDX-License-Identifier: LicenseRef-Nordic-5-Clause
 *
 */

#include <stdio.h>
#include <unistd.h>
#include <zephyr/kernel.h>

#define TWI_MASTER NRF_TWIM1_NS
#define GPIO       NRF_P0_NS
#define PIN_SCL    2
#define PIN_SDA    3

extern uint8_t tx_buffer[1024];
extern uint8_t rx_buffer[2048];

int lp_printf(const char *fmt, ...);

K_SEM_DEFINE(twim_done, 0, 1);
static bool error = false;

void twim_isr(const void *arg)
{
	if (TWI_MASTER->EVENTS_STOPPED) {
		TWI_MASTER->EVENTS_STOPPED = 0;
	}
	if (TWI_MASTER->EVENTS_ERROR) {
		error = true;
		TWI_MASTER->EVENTS_ERROR = 0;
	}
	k_sem_give(&twim_done);
}

void twim_init(uint32_t bitrate)
{
	/* SCK: Dir input, input disconnect, pull up, drive s0d1, sense disabled. */
	GPIO->PIN_CNF[PIN_SCL] = (GPIO_PIN_CNF_INPUT_Disconnect << GPIO_PIN_CNF_INPUT_Pos) |
				 (GPIO_PIN_CNF_PULL_Pullup << GPIO_PIN_CNF_PULL_Pos) |
				 (GPIO_PIN_CNF_DRIVE_S0D1 << GPIO_PIN_CNF_DRIVE_Pos);
	/* MOSI: Dir input, input disconnect, pull up, drive s0d1, sense disabled. */
	GPIO->PIN_CNF[PIN_SDA] = (GPIO_PIN_CNF_INPUT_Disconnect << GPIO_PIN_CNF_INPUT_Pos) |
				 (GPIO_PIN_CNF_PULL_Pullup << GPIO_PIN_CNF_PULL_Pos) |
				 (GPIO_PIN_CNF_DRIVE_S0D1 << GPIO_PIN_CNF_DRIVE_Pos);

	/* Configure pins. */
	TWI_MASTER->PSEL.SCL = PIN_SCL;
	TWI_MASTER->PSEL.SDA = PIN_SDA;

	/* Configure buffers. */
	TWI_MASTER->RXD.PTR = (int)rx_buffer;
	TWI_MASTER->TXD.PTR = (int)tx_buffer;

	/* Configure. */
	TWI_MASTER->FREQUENCY = bitrate;
	TWI_MASTER->ADDRESS = 42;

	/* Stop after transfer. */
	TWI_MASTER->SHORTS = TWIM_SHORTS_LASTTX_STOP_Msk | TWIM_SHORTS_LASTRX_STOP_Msk;

	/* Enable interrupt to wake up at the end of a message. */
	TWI_MASTER->INTENSET = TWIM_INTENSET_STOPPED_Msk | TWIM_INTENSET_ERROR_Msk;
	irq_connect_dynamic(SPIM1_SPIS1_TWIM1_TWIS1_UARTE1_IRQn, 0, twim_isr, NULL, 0);
	irq_enable(SPIM1_SPIS1_TWIM1_TWIS1_UARTE1_IRQn);

	/* Enable. */
	TWI_MASTER->ENABLE = TWIM_ENABLE_ENABLE_Enabled;

	lp_printf("    SCL     P0.%02d\n", PIN_SCL);
	lp_printf("    SDA     P0.%02d\n", PIN_SDA);
}

int twim_send(int size)
{
	int err = 0;

	error = false;

	TWI_MASTER->TXD.MAXCNT = size;
	TWI_MASTER->TASKS_STARTTX = 1;

	k_sem_take(&twim_done, K_FOREVER);

	if (error) {
		err = TWI_MASTER->ERRORSRC;
		TWI_MASTER->ERRORSRC = err;
		TWI_MASTER->TASKS_STOP = 1;
		k_sem_take(&twim_done, K_FOREVER);
		return -err;
	}

	return TWI_MASTER->TXD.AMOUNT;
}

int twim_recv(int size)
{
	int err = 0;

	error = false;

	TWI_MASTER->RXD.MAXCNT = size;
	TWI_MASTER->TASKS_STARTRX = 1;

	k_sem_take(&twim_done, K_FOREVER);

	if (error) {
		err = TWI_MASTER->ERRORSRC;
		TWI_MASTER->ERRORSRC = err;
		TWI_MASTER->TASKS_STOP = 1;
		k_sem_take(&twim_done, K_FOREVER);
		return -err;
	}

	return TWI_MASTER->RXD.AMOUNT;
}

void twim_deinit(void)
{
	TWI_MASTER->INTENCLR = TWIM_INTENCLR_STOPPED_Msk| TWIM_INTENCLR_ERROR_Msk;
	TWI_MASTER->SHORTS = 0;
	GPIO->PIN_CNF[PIN_SCL] = 0;
	GPIO->PIN_CNF[PIN_SDA] = 0;
	TWI_MASTER->ENABLE = 0;
}
```

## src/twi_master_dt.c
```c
/*
 * Copyright (c) 2024 Nordic Semiconductor ASA
 *
 * SPDX-License-Identifier: LicenseRef-Nordic-5-Clause
 *
 */

#include <zephyr/drivers/i2c.h>
#include <zephyr/pm/device.h>

#define USED_DEV DT_NODELABEL(twi_master)
#define DT_DRV_COMPAT nordic_nrf_twim

const struct device *p_dev;

void init(void)
{
	p_dev = DEVICE_DT_GET(USED_DEV);

	if (p_dev == NULL) {
		lp_printf("Could not get device\n");
		return;
	}
	lp_printf("\nUsing TWI Master device %s\n", p_dev->name);
}

void send(int size)
{
	int err = i2c_write(p_dev, tx_buffer, size, 42);

	lp_printf("err = %d\n", err);
}

int recv(int size, int timeout)
{
	return i2c_read(p_dev, rx_buffer, size, 42);
}

void deinit(void)
{

}
```

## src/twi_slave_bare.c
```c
/*
 * Copyright (c) 2024 Nordic Semiconductor ASA
 *
 * SPDX-License-Identifier: LicenseRef-Nordic-5-Clause
 *
 */

#include <stdio.h>
#include <unistd.h>
#include <zephyr/kernel.h>

#define TWI_SLAVE  NRF_TWIS1_NS
#define GPIO       NRF_P0_NS
#define PIN_SCL    2
#define PIN_SDA    3

extern uint8_t tx_buffer[1024];
extern uint8_t rx_buffer[2048];

int lp_printf(const char *fmt, ...);

K_SEM_DEFINE(twis_done, 0, 1);

void twis_isr(const void *arg)
{
	if (TWI_SLAVE->EVENTS_STOPPED) {
		k_sem_give(&twis_done);
		TWI_SLAVE->EVENTS_STOPPED = 0;
	}
	if (TWI_SLAVE->EVENTS_READ) {
		TWI_SLAVE->TASKS_PREPARETX = 1;
		TWI_SLAVE->TASKS_RESUME = 1;
		TWI_SLAVE->EVENTS_READ = 0;
	}
	if (TWI_SLAVE->EVENTS_WRITE) {
		TWI_SLAVE->TASKS_PREPARERX = 1;
		TWI_SLAVE->TASKS_RESUME = 1;
		TWI_SLAVE->EVENTS_WRITE = 0;
	}
}

void twis_init(uint32_t bitrate)
{
	/* SCK: Dir output, input disconnect, pull up, drive h0d1, sense disabled. */
	GPIO->PIN_CNF[PIN_SCL] = (GPIO_PIN_CNF_INPUT_Disconnect << GPIO_PIN_CNF_INPUT_Pos) |
				 (GPIO_PIN_CNF_PULL_Pullup << GPIO_PIN_CNF_PULL_Pos) |
				 (GPIO_PIN_CNF_DRIVE_S0D1 << GPIO_PIN_CNF_DRIVE_Pos);
	/* MOSI: Dir output, input disconnect, pull up, drive h0d1, sense disabled. */
	GPIO->PIN_CNF[PIN_SDA] = (GPIO_PIN_CNF_INPUT_Disconnect << GPIO_PIN_CNF_INPUT_Pos) |
				 (GPIO_PIN_CNF_PULL_Pullup << GPIO_PIN_CNF_PULL_Pos) |
				 (GPIO_PIN_CNF_DRIVE_S0D1 << GPIO_PIN_CNF_DRIVE_Pos);

	/* Configure pins. */
	TWI_SLAVE->PSEL.SCL = PIN_SCL;
	TWI_SLAVE->PSEL.SDA = PIN_SDA;

	/* Configure buffers. */
	TWI_SLAVE->RXD.PTR = (int)rx_buffer;
	TWI_SLAVE->RXD.MAXCNT = 0;
	TWI_SLAVE->TXD.PTR = (int)tx_buffer;
	TWI_SLAVE->TXD.MAXCNT = 0;

	/* Configure. */
	TWI_SLAVE->ADDRESS[0] = 42;
	TWI_SLAVE->CONFIG = TWIS_CONFIG_ADDRESS0_Msk;
	/* Suspend after we have received a READ or WRITE flag so we can either start RX or TX. */
	TWI_SLAVE->SHORTS = TWIS_SHORTS_READ_SUSPEND_Msk | TWIS_SHORTS_WRITE_SUSPEND_Msk;

	/* Enable interrupt to wake up at the end of a message. */
	TWI_SLAVE->INTENSET = TWIS_INTENSET_STOPPED_Msk | TWIS_INTENSET_READ_Msk |
			      TWIS_INTENSET_WRITE_Msk;
	irq_connect_dynamic(SPIM1_SPIS1_TWIM1_TWIS1_UARTE1_IRQn, 0, twis_isr, NULL, 0);
	irq_enable(SPIM1_SPIS1_TWIM1_TWIS1_UARTE1_IRQn);

	/* Enable. */
	TWI_SLAVE->ENABLE = TWIS_ENABLE_ENABLE_Enabled;

	lp_printf("    SCL     P0.%02d\n", PIN_SCL);
	lp_printf("    SDA     P0.%02d\n", PIN_SDA);
}

int twis_send(int size)
{
	TWI_SLAVE->TXD.MAXCNT = size;

	if (k_sem_take(&twis_done,  K_SECONDS(60))) {
		return -ETIMEDOUT;
	}

	if (!TWI_SLAVE->EVENTS_TXSTARTED) {
		return -EBADR;	/* Got RX instead of TX. */
	}

	TWI_SLAVE->EVENTS_TXSTARTED = 0;

	return TWI_SLAVE->TXD.AMOUNT;
}

int twis_recv(int size)
{
	TWI_SLAVE->RXD.MAXCNT = size;

	if (k_sem_take(&twis_done,  K_SECONDS(60))) {
		return -ETIMEDOUT;
	}

	if (!TWI_SLAVE->EVENTS_RXSTARTED) {
		return -EBADR;	/* Got TX instead of RX. */
	}

	TWI_SLAVE->EVENTS_RXSTARTED = 0;

	return TWI_SLAVE->RXD.AMOUNT;
}

void twis_deinit(void)
{
	TWI_SLAVE->INTENCLR = TWIS_INTENCLR_STOPPED_Msk | TWIS_INTENCLR_READ_Msk |
			      TWIS_INTENCLR_WRITE_Msk;
	TWI_SLAVE->SHORTS = 0;
	GPIO->PIN_CNF[PIN_SCL] = 0;
	GPIO->PIN_CNF[PIN_SDA] = 0;
	TWI_SLAVE->ENABLE = 0;
}
```

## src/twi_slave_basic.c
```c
/*
 * Copyright (c) 2024 Nordic Semiconductor ASA
 *
 * SPDX-License-Identifier: LicenseRef-Nordic-5-Clause
 *
 */

#include <stdio.h>
#include <unistd.h>
#include <zephyr/kernel.h>

#define TWI_SLAVE  NRF_TWIS1_NS
#define GPIO       NRF_P0_NS
#define PIN_SCL    2
#define PIN_SDA    3

extern uint8_t tx_buffer[1024];
extern uint8_t rx_buffer[2048];

int lp_printf(const char *fmt, ...);

static bool transfer_done = false;

void twis_isr(const void *arg)
{
	if (TWI_SLAVE->EVENTS_STOPPED) {
		transfer_done = true;
		TWI_SLAVE->EVENTS_STOPPED = 0;
	}
	if (TWI_SLAVE->EVENTS_READ) {
		TWI_SLAVE->TASKS_PREPARETX = 1;
		TWI_SLAVE->TASKS_RESUME = 1;
		TWI_SLAVE->EVENTS_READ = 0;
	}
	if (TWI_SLAVE->EVENTS_WRITE) {
		TWI_SLAVE->TASKS_PREPARERX = 1;
		TWI_SLAVE->TASKS_RESUME = 1;
		TWI_SLAVE->EVENTS_WRITE = 0;
	}
}

void twis_init(uint32_t bitrate)
{
	/* SCK: Dir output, input disconnect, pull up, drive h0d1, sense disabled. */
	GPIO->PIN_CNF[PIN_SCL] = (GPIO_PIN_CNF_INPUT_Disconnect << GPIO_PIN_CNF_INPUT_Pos) |
				 (GPIO_PIN_CNF_PULL_Pullup << GPIO_PIN_CNF_PULL_Pos) |
				 (GPIO_PIN_CNF_DRIVE_S0D1 << GPIO_PIN_CNF_DRIVE_Pos);
	/* MOSI: Dir output, input disconnect, pull up, drive h0d1, sense disabled. */
	GPIO->PIN_CNF[PIN_SDA] = (GPIO_PIN_CNF_INPUT_Disconnect << GPIO_PIN_CNF_INPUT_Pos) |
				 (GPIO_PIN_CNF_PULL_Pullup << GPIO_PIN_CNF_PULL_Pos) |
				 (GPIO_PIN_CNF_DRIVE_S0D1 << GPIO_PIN_CNF_DRIVE_Pos);

	/* Configure pins. */
	TWI_SLAVE->PSEL.SCL = PIN_SCL;
	TWI_SLAVE->PSEL.SDA = PIN_SDA;

	/* Configure buffers. */
	TWI_SLAVE->RXD.PTR = (int)rx_buffer;
	TWI_SLAVE->RXD.MAXCNT = 0;
	TWI_SLAVE->TXD.PTR = (int)tx_buffer;
	TWI_SLAVE->TXD.MAXCNT = 0;

	/* Configure. */
	TWI_SLAVE->ADDRESS[0] = 42;
	TWI_SLAVE->CONFIG = TWIS_CONFIG_ADDRESS0_Msk;
	TWI_SLAVE->SHORTS = TWIS_SHORTS_READ_SUSPEND_Msk | TWIS_SHORTS_WRITE_SUSPEND_Msk;

	/* Enable interrupt to wake up at the end of a message. */
	TWI_SLAVE->INTENSET = TWIS_INTENSET_STOPPED_Msk | TWIS_INTENSET_READ_Msk |
			      TWIS_INTENSET_WRITE_Msk;
	irq_connect_dynamic(SPIM1_SPIS1_TWIM1_TWIS1_UARTE1_IRQn, 0, twis_isr, NULL, 0);
	irq_enable(SPIM1_SPIS1_TWIM1_TWIS1_UARTE1_IRQn);

	/* Enable. */
	TWI_SLAVE->ENABLE = TWIS_ENABLE_ENABLE_Enabled;

	lp_printf("    SCL     P0.%02d\n", PIN_SCL);
	lp_printf("    SDA     P0.%02d\n", PIN_SDA);
}

int twis_send(int size)
{
	TWI_SLAVE->TXD.MAXCNT = size;

	while (!TWI_SLAVE->EVENTS_TXSTARTED || !transfer_done) {
		__WFI();
	}

	transfer_done = false;
	TWI_SLAVE->EVENTS_TXSTARTED = 0;

	return TWI_SLAVE->TXD.AMOUNT;
}

int twis_recv(int size)
{
	TWI_SLAVE->RXD.MAXCNT = size;

	while (!TWI_SLAVE->EVENTS_RXSTARTED || !transfer_done) {
		__WFI();
	}

	transfer_done = false;
	TWI_SLAVE->EVENTS_RXSTARTED = 0;

	return TWI_SLAVE->RXD.AMOUNT;
}

void twis_deinit(void)
{
	TWI_SLAVE->INTENCLR = TWIS_INTENCLR_STOPPED_Msk | TWIS_INTENCLR_READ_Msk |
			      TWIS_INTENCLR_WRITE_Msk;
	TWI_SLAVE->SHORTS = 0;
	GPIO->PIN_CNF[PIN_SCL] = 0;
	GPIO->PIN_CNF[PIN_SDA] = 0;
	TWI_SLAVE->ENABLE = 0;
}
```

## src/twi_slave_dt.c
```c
/*
 * Copyright (c) 2024 Nordic Semiconductor ASA
 *
 * SPDX-License-Identifier: LicenseRef-Nordic-5-Clause
 *
 */

#include <zephyr/drivers/i2c.h>
#include <zephyr/pm/device.h>

#define USED_DEV DT_NODELABEL(twi_slave)
// #define DT_DRV_COMPAT nordic_nrf_twis
#define TWI_SLAVE NRF_TWIS1_NS

K_SEM_DEFINE(i2c_done, 0, 1);

const struct device *p_dev;
size_t transfer_len;

void buf_write_received_cb(struct i2c_target_config *config, uint8_t *ptr, uint32_t len)
{
	memcpy(rx_buffer, ptr, len);
	transfer_len = len;
	k_sem_give(&i2c_done);
}

int buf_read_requested_cb(struct i2c_target_config *config, uint8_t **ptr, uint32_t *len)
{
	*ptr = tx_buffer;
	*len = transfer_len;

	k_sem_give(&i2c_done);

	return 0;
}

static struct i2c_target_callbacks callbacks = {
	.buf_write_received = buf_write_received_cb,
	.buf_read_requested = buf_read_requested_cb
};

static struct i2c_target_config config = {
	.address = 42,
	.callbacks = &callbacks
};

void init(void)
{
	p_dev = DEVICE_DT_GET(USED_DEV);

	if (p_dev == NULL) {
		lp_printf("Could not get device\n");
		return;
	}

	int err = i2c_target_register(p_dev, &config);

	if (err) {
		lp_printf("Failed to register slave, err %d\n", err);
	}

	lp_printf("\nUsing TWI Slave device: %s\n", p_dev->name);
	lp_printf("    SCL     P0.%02d\n", TWI_SLAVE->PSEL.SCL);
	lp_printf("    SDA     P0.%02d\n", TWI_SLAVE->PSEL.SDA);
}

int send(int size)
{
	transfer_len = size;

	k_sem_take(&i2c_done, K_FOREVER);

	return transfer_len;
}

int recv(int size)
{
	transfer_len = 0;

	k_sem_take(&i2c_done, K_FOREVER);

	return transfer_len;
}

void deinit(void)
{

}
```
